# STM32F072xB register map
File version: 1.0
Registers are 32-bit, read-write, reset 0x0 unless marked. A register's access mark holds for its fields unless they carry their own. Offsets are from the block's base; [hi:lo] are bit positions; {n}, {i} and the like mark numbered series.

## TIM6 — TIM
Base 0x40001000
Same registers: TIM7 0x40001400
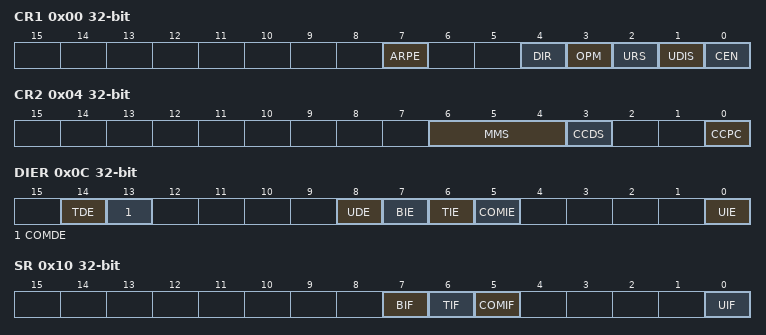
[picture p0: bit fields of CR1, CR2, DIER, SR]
0x00 CR1 — TIM control register 1
  [7] ARPE — Auto-reload preload enable
  [4] DIR — Direction
    0=UP (Timer counter counts up); 1=DOWN (Timer counter counts down)
  [3] OPM — One pulse mode
    1=SINGLE (Counter stops counting at the next update event); 0=REPETITIVE (Counter is not stopped at update event)
  [2] URS — Update request source
    0=REGULAR (Counter overflow/underflow, Setting the UG bit or Update generation through the slave mode controller generates an update request); 1=COUNTER (Only counter overflow/underflow generates an update request)
  [1] UDIS — Update disable
  [0] CEN — Counter enable
0x04 CR2 — TIM control register 2
  [6:4] MMS — MMS[2:0] bits (Master Mode Selection)
    0=RESET (UG bit from the TIMx_EGR register is used as trigger output); 1=ENABLE (Counter Enable signal (CNT_EN) is used as trigger output); 2=UPDATE (Update event is used as trigger output); 3=CC1IF (CC1 capture or a compare match is used as trigger output); {v}=OC{v-3}REF (OC{v-3}REF signal is used as trigger output) (v=4..7)
  [3] CCDS — Capture/Compare DMA Selection
    0=CC (CCx DMA request sent when CCx event occurs); 1=UPDATE (CCx DMA requests sent when update event occurs)
  [0] CCPC — Capture/Compare Preloaded Control
0x08 SMCR — TIM slave Mode Control register
  [3] OCCS — OCREF clear selection
    0=OCREF_CLR (OCREF_CLR_INT is connected to the OCREF_CLR input); 1=ETR (OCREF_CLR_INT is connected to ETRF)
0x0C DIER — TIM DMA/interrupt enable register
  [14] TDE — Trigger DMA request enable
  [13] COMDE — COM DMA request enable
  [8] UDE — Update DMA request enable
  [7] BIE — Break interrupt enable
  [6] TIE — Trigger interrupt enable
  [5] COMIE — COM interrupt enable
  [0] UIE — Update interrupt enable
0x10 SR — TIM status register
  [7] BIF — Break interrupt Flag
  [6] TIF — Trigger interrupt Flag
  [5] COMIF — COM interrupt Flag
  [0] UIF — Update interrupt Flag
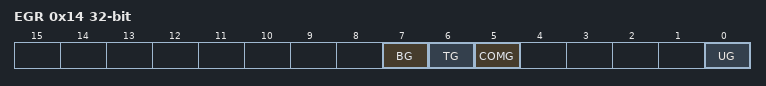
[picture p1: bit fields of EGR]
0x14 EGR — TIM event generation register
  [7] BG — Break Generation
  [6] TG — Trigger Generation
  [5] COMG — Capture/Compare Control Update Generation
  [0] UG — Update Generation
0x24 CNT — TIM counter register
  [15:0] CNT — Counter Value
0x28 PSC — TIM prescaler register
  [15:0] PSC — Prescaler Value
0x2C ARR — TIM auto-reload register
  [15:0] ARR — actual auto-reload Value
0x4C DMAR — TIM DMA address for full transfer register
  [15:0] DMAB — DMA register for burst accesses
0x50 OR — TIM option register

## WWDG — Window WATCHDOG
Base 0x40002C00
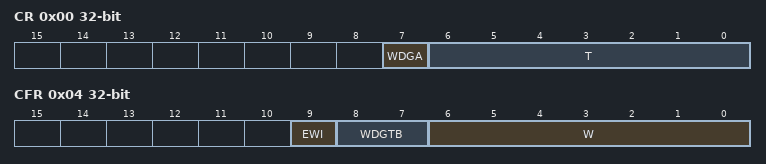
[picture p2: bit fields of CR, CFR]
0x00 CR — WWDG Control register
  [7] WDGA — Activation bit
  [6:0] T — T[6:0] bits (7-Bit counter (MSB to LSB))
0x04 CFR — WWDG Configuration register
  [9] EWI — Early Wakeup Interrupt
  [8:7] WDGTB — WDGTB[1:0] bits (Timer Base)
    0=PRESCALER_1 (WWDG counter clock = (PCLK1/4096)/1); 1=PRESCALER_2 (WWDG counter clock = (PCLK1/4096)/2); 2=PRESCALER_4 (WWDG counter clock = (PCLK1/4096)/4); 3=PRESCALER_8 (WWDG counter clock = (PCLK1/4096)/8)
  [6:0] W — W[6:0] bits (7-bit window value)
0x08 SR — WWDG Status register
  [0] EWIF — Early Wakeup Interrupt Flag

## IWDG — Independent WATCHDOG
Base 0x40003000
0x00 KR — IWDG Key register
  [15:0] KEY — Key value (write only, read 0000h)
0x04 PR — IWDG Prescaler register
  [2:0] PR — PR[2:0] (Prescaler divider)
0x08 RLR — IWDG Reload register
  [11:0] RL — Watchdog counter reload value
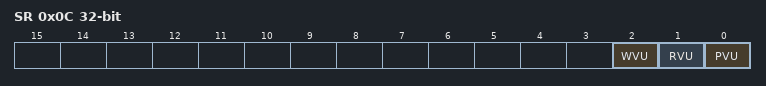
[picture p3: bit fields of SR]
0x0C SR — IWDG Status register
  [2] WVU — Watchdog counter window value update
  [1] RVU — Watchdog counter reload value update
  [0] PVU — Watchdog prescaler value update
0x10 WINR — IWDG Window register
  [11:0] WIN — Watchdog counter window value

## I2C2 — Inter-integrated Circuit Interface
Base 0x40005800
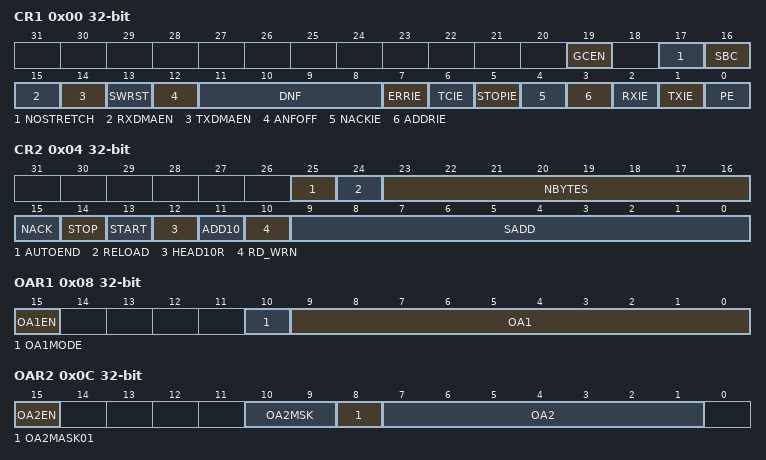
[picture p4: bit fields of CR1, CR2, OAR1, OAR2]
0x00 CR1 — I2C Control register 1
  [19] GCEN — General call enable
  [17] NOSTRETCH — Clock stretching disable
  [16] SBC — Slave byte control
  [15] RXDMAEN — DMA reception requests enable
  [14] TXDMAEN — DMA transmission requests enable
  [13] SWRST — Software reset
  [12] ANFOFF — Analog noise filter OFF
  [11:8] DNF — Digital noise filter
  [7] ERRIE — Errors interrupt enable
  [6] TCIE — Transfer complete interrupt enable
  [5] STOPIE — STOP detection interrupt enable
  [4] NACKIE — NACK received interrupt enable
  [3] ADDRIE — Address match interrupt enable
  [2] RXIE — RX interrupt enable
  [1] TXIE — TX interrupt enable
  [0] PE — Peripheral enable
0x04 CR2 — I2C Control register 2
  [25] AUTOEND — Automatic end mode (master mode)
  [24] RELOAD — NBYTES reload mode
  [23:16] NBYTES — Number of bytes
  [15] NACK — NACK generation (slave mode)
    0=ACK (ACK is sent after current received byte.); 1=NACK (NACK is sent after current received byte.)
  [14] STOP — STOP generation (master mode)
  [13] START — START generation
  [12] HEAD10R — 10-bit address header only read direction (master mode)
  [11] ADD10 — 10-bit addressing mode (master mode)
    0=MODE_7BIT (Master operates in 7-bit addressing mode.); 1=MODE_10BIT (Master operates in 10-bit addressing mode.)
  [10] RD_WRN — Transfer direction (master mode)
    0=WRITE (Master request a write transfer.); 1=READ (Master request a read transfer.)
  [9:0] SADD — Slave address (master mode)
0x08 OAR1 — I2C Own address 1 register
  [15] OA1EN — Own address 1 enable
  [10] OA1MODE — Own address 1 10-bit mode
  [9:0] OA1 — Interface own address 1
0x0C OAR2 — I2C Own address 2 register
  [15] OA2EN — Own address 2 enable
  [10:9] OA2MSK — Own address 2 masks
  [8] OA2MASK01 — OA2[1] is masked, Only OA2[7:2] are compared
  [7:1] OA2 — Interface own address 2
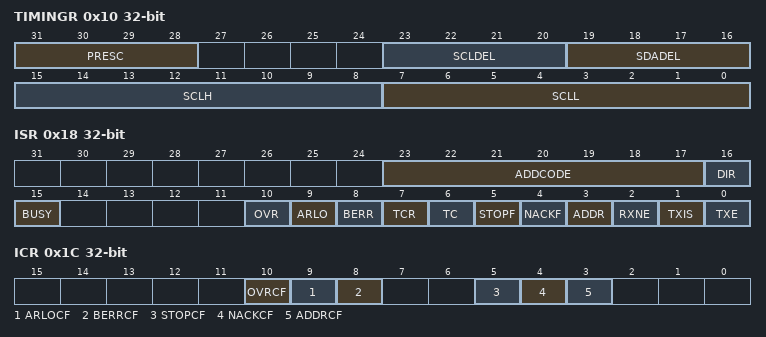
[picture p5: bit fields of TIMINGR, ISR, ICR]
0x10 TIMINGR — I2C Timing register
  [31:28] PRESC — Timings prescaler
  [23:20] SCLDEL — Data setup time
  [19:16] SDADEL — Data hold time
  [15:8] SCLH — SCL high period (master mode)
  [7:0] SCLL — SCL low period (master mode)
0x18 ISR — I2C Interrupt and status register
  [23:17] ADDCODE — Address match code (slave mode)
  [16] DIR — Transfer direction (slave mode)
    0=WRITE; 1=READ
  [15] BUSY — Bus busy
  [10] OVR — Overrun/Underrun
  [9] ARLO — Arbitration lost
  [8] BERR — Bus error
  [7] TCR — Transfer complete reload
  [6] TC — Transfer complete (master mode)
  [5] STOPF — STOP detection flag
  [4] NACKF — NACK received flag
  [3] ADDR — Address matched (slave mode)
  [2] RXNE — Receive data register not empty
  [1] TXIS — Transmit interrupt status
  [0] TXE — Transmit data register empty
0x1C ICR — I2C Interrupt clear register
  [10] OVRCF — Overrun/Underrun clear flag
  [9] ARLOCF — Arbitration lost clear flag
  [8] BERRCF — Bus error clear flag
  [5] STOPCF — STOP detection clear flag
  [4] NACKCF — NACK clear flag
  [3] ADDRCF — Address matched clear flag
0x24 RXDR — I2C Receive data register
  [7:0] RXDATA — 8-bit receive data
0x28 TXDR — I2C Transmit data register
  [7:0] TXDATA — 8-bit transmit data
